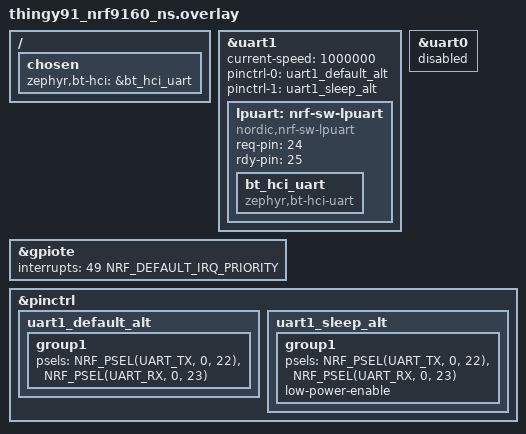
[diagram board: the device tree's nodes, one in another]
/ {
	chosen {
		zephyr,bt-hci = &bt_hci_uart;
	};
};

&uart1 {
	current-speed = <1000000>;
	status = "okay";
	/delete-property/ hw-flow-control;

	pinctrl-0 = <&uart1_default_alt>;
	pinctrl-1 = <&uart1_sleep_alt>;
	pinctrl-names = "default", "sleep";
	lpuart: nrf-sw-lpuart {
		compatible = "nordic,nrf-sw-lpuart";
		status = "okay";
		req-pin = <24>;
		rdy-pin = <25>;
		bt_hci_uart: bt_hci_uart {
			compatible = "zephyr,bt-hci-uart";
			status = "okay";
		};
	};
};

&gpiote {
	interrupts = <49 NRF_DEFAULT_IRQ_PRIORITY>;
};

&uart0 {
	status = "disabled";
};

&pinctrl {
	uart1_default_alt: uart1_default_alt {
		group1 {
			psels = <NRF_PSEL(UART_TX, 0, 22)>,
				<NRF_PSEL(UART_RX, 0, 23)>;
		};
	};

	uart1_sleep_alt: uart1_sleep_alt {
		group1 {
			psels = <NRF_PSEL(UART_TX, 0, 22)>,
				<NRF_PSEL(UART_RX, 0, 23)>;
			low-power-enable;
		};
	};
};
